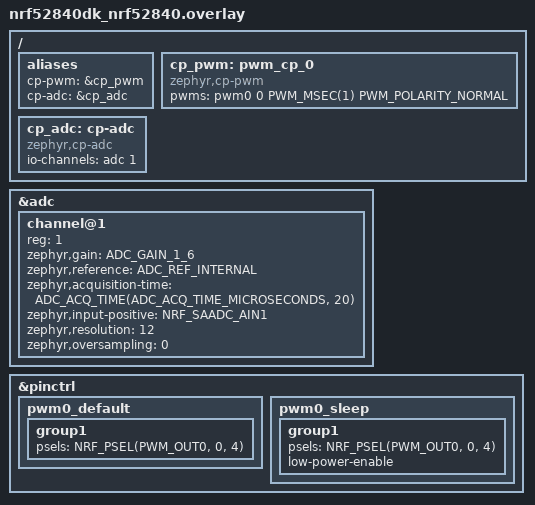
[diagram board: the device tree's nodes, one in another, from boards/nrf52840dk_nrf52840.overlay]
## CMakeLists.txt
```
# SPDX-License-Identifier: Apache-2.0

cmake_minimum_required(VERSION 3.13.1)
find_package(Zephyr REQUIRED HINTS $ENV{ZEPHYR_BASE})

project(app LANGUAGES C)

target_sources(app PRIVATE src/main.c)
```

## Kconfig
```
# SPDX-License-Identifier: Apache-2.0
#

menu "Zephyr"
source "Kconfig.zephyr"
endmenu

module = APP
module-str = APP
source "subsys/logging/Kconfig.template.log_config"
```

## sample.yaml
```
# This file is provided so that the application can be compiled using Twister,
# the Zephyr testing tool. In this file, multiple combinations can be specified,
# so that you can easily test all of them locally or in CI.
sample:
  description: AC charge application
  name: ac_charge
common:
  build_only: true
  integration_platforms:
    - custom_plank
tests:
  app.default: {}
  app.debug:
    extra_overlay_confs:
      - debug.conf
```

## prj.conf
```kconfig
# SPDX-License-Identifier: Apache-2.0
#
# This file contains selected Kconfig options for the application.

CONFIG_LOG=y
CONFIG_APP_LOG_LEVEL_INF=y
CONFIG_AC_CHARGE_LOG_LEVEL_DBG=y

# Enable AC charge library
CONFIG_PWM=y
CONFIG_ADC=y
CONFIG_SMF=y
CONFIG_LIB_AC_CHARGE=y

# Enable the shell
CONFIG_SHELL=y
```

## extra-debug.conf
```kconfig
# SPDX-License-Identifier: Apache-2.0
#
# Extra debug config

# Enable debugging symbols
CONFIG_DEBUG=y
CONFIG_DEBUG_THREAD_INFO=y

# Disable optimizations for better debugging
CONFIG_NO_OPTIMIZATIONS=y

CONFIG_ENTROPY_GENERATOR=y
CONFIG_STACK_CANARIES=y
```

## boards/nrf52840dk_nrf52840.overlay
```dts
/*
 * SPDX-License-Identifier: Apache-2.0
 */

#include <zephyr/dt-bindings/adc/adc.h>

/ {
    aliases {
        cp-pwm = &cp_pwm;
        cp-adc = &cp_adc;
    };

    cp_pwm: pwm_cp_0 {
        compatible = "zephyr,cp-pwm";
        pwms = <&pwm0 0 PWM_MSEC(1) PWM_POLARITY_NORMAL>;
    };

    cp_adc: cp-adc {
        /* CP front-end is biased/divided to fit SAADC input range. */
        compatible = "zephyr,cp-adc";
        io-channels = <&adc 1>;
    };
};

&adc {
    #address-cells = <1>;
    #size-cells = <0>;

    channel@1 {
        reg = <1>;
        zephyr,gain = "ADC_GAIN_1_6";
        zephyr,reference = "ADC_REF_INTERNAL";
        zephyr,acquisition-time = <ADC_ACQ_TIME(ADC_ACQ_TIME_MICROSECONDS, 20)>;
        zephyr,input-positive = <NRF_SAADC_AIN1>; /* P0.03 / Arduino A0 */
        zephyr,resolution = <12>;
        zephyr,oversampling = <0>;
    };
};

/* Set CP PWM pin */
&pinctrl {
    pwm0_default: pwm0_default {
        group1 {
            psels = <NRF_PSEL(PWM_OUT0, 0, 4)>;
        };
    };
    pwm0_sleep: pwm0_sleep {
        group1 {
            psels = <NRF_PSEL(PWM_OUT0, 0, 4)>;
            low-power-enable;
        };
    };
};
```

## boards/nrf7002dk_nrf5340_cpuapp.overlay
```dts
/*
 * SPDX-License-Identifier: Apache-2.0
 */

#include <zephyr/dt-bindings/adc/adc.h>

/ {
    aliases {
        cp-pwm = &cp_pwm;
        cp-adc = &cp_adc;
    };

    cp_pwm: pwm_cp_0 {
        compatible = "zephyr,cp-pwm";
        pwms = <&pwm0 0 PWM_MSEC(1) PWM_POLARITY_NORMAL>;
    };

    cp_adc: cp-adc {
        /* CP front-end is biased/divided to fit SAADC input range. */
        compatible = "zephyr,cp-adc";
        io-channels = <&adc 1>;
    };
};

&adc {
    #address-cells = <1>;
    #size-cells = <0>;

    channel@1 {
        reg = <1>;
        zephyr,gain = "ADC_GAIN_1_6";
        zephyr,reference = "ADC_REF_INTERNAL";
        zephyr,acquisition-time = <ADC_ACQ_TIME(ADC_ACQ_TIME_MICROSECONDS, 20)>;
        zephyr,input-positive = <NRF_SAADC_AIN0>; /* P0.04 / Arduino A0 */
        zephyr,resolution = <12>;
        zephyr,oversampling = <0>;
    };
};

/* Set CP PWM pin */
&pinctrl {
    pwm0_default: pwm0_default {
        group1 {
            psels = <NRF_PSEL(PWM_OUT0, 0, 5)>;
        };
    };
    pwm0_sleep: pwm0_sleep {
        group1 {
            psels = <NRF_PSEL(PWM_OUT0, 0, 5)>;
            low-power-enable;
        };
    };
};
```

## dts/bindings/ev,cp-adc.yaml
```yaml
# SPDX-License-Identifier: Apache-2.0

description: EV charger control pilot ADC endpoint

compatible: "zephyr,cp-adc"

include: base.yaml

properties:
  io-channels:
    type: phandle-array
    required: true
    description: ADC channel used to sample the conditioned control pilot signal.
```

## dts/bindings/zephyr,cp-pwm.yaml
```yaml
# SPDX-License-Identifier: Apache-2.0

description: EV charger control pilot PWM endpoint

compatible: "zephyr,cp-pwm"

include: base.yaml

properties:
  pwms:
    type: phandle-array
    required: true
    description: PWM output used to generate the control pilot signal.
```

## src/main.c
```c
/*
 * SPDX-License-Identifier: Apache-2.0
 */

#include <zephyr/kernel.h>
#include <zephyr/logging/log.h>

#include <app_version.h>
#include <lib/ac_charge.h>

LOG_MODULE_REGISTER(main, CONFIG_APP_LOG_LEVEL);

int main(void)
{
    int ret;
    struct cp_measurement cp;
    LOG_INF("Start ac_charge, version %s", APP_VERSION_STRING);

    ret = init_ac_charge();
    if (ret < 0) {
        LOG_ERR("init ac_charge failed, ret: %d", ret);
    }

    while (1) {
        if (cp_sense_get_latest(&cp) == 0) {
            ac_charge_sm_update_from_cp(&cp);
        }

        ret = ac_charge_sm_step();
        if (ret < 0) {
            LOG_ERR("ac_charge_sm_step failed: %d", ret);
        }

        k_sleep(K_SECONDS(1));
    }
}
```
